# GD32A72_A74x register map
File version: 1.0
CPU: CM7 r2p1, little endian, MPU, FPU, DSP, 4 interrupt priority bits
Registers are 32-bit, read-write, reset 0x0 unless marked. A register's access mark holds for its fields unless they carry their own. Offsets are from the block's base; [hi:lo] are bit positions; {n}, {i} and the like mark numbered series.

## CMP1 — Comparator
Base 0x40016C00
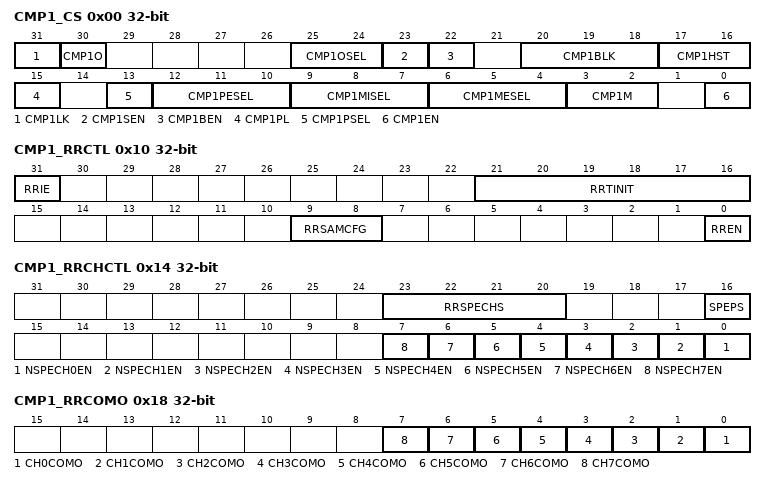
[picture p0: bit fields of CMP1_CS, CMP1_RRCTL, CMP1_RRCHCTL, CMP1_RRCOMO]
0x00 CMP1_CS access per field — CMP1 Control status register
  [31] CMP1LK rw — CMP1 lock
  [30] CMP1O ro — CMP1 output state
  [25:24] CMP1OSEL rw — CMP1 output selection
  [23] CMP1SEN rw — Voltage scaler enable bit
  [22] CMP1BEN rw — Scaler bridge enable bit
  [20:18] CMP1BLK rw — CMP1 output blanking source
  [17:16] CMP1HST rw — CMP1 hysteresis
  [15] CMP1PL rw — Polarity of CMP1 output
  [13] CMP1PSEL rw — CMP1_IP input selection
  [12:10] CMP1PESEL rw — CMP1_IP external input selection
  [9:7] CMP1MISEL rw — CMP1_IM internal input selection
  [6:4] CMP1MESEL rw — CMP1_IM external input selection
  [3:2] CMP1M rw — CMP1 mode
  [0] CMP1EN rw — CMP1 enable
0x10 CMP1_RRCTL — Round Robin control register
  [31] RRIE — Interrupt enable for Round-Robin
  [21:16] RRTINIT — Round-Robin time initialization
  [9:8] RRSAMCFG — Round-Robin sample clocks configuration
  [0] RREN — Round-Robin enable
0x14 CMP1_RRCHCTL — Round Robin channel control register
  [23:20] RRSPECHS — Round-Robin specified channel selection
  [16] SPEPS — Specified port selection
  [n] NSPECH{n}EN (n=0..7) — Non-specified mux port channel {n} enable
0x18 CMP1_RRCOMO — Round Robin compare output register
  [n] CH{n}COMO (n=0..7) — Channel {n} compare output state
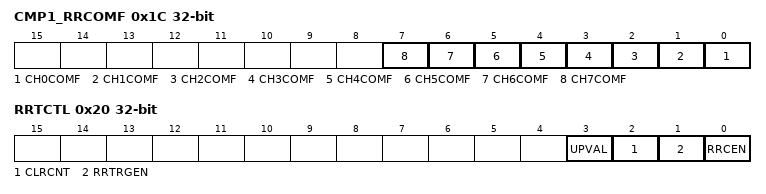
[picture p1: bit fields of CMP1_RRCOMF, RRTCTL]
0x1C CMP1_RRCOMF — Round Robin compare result flag register
  [n] CH{n}COMF (n=0..7) — Channel {n} compare result flag
0x20 RRTCTL — Round Robin timer control register
  [3] UPVAL — Write 1 to update the RRTVAL[31:0] value
  [2] CLRCNT — Write 1 to clear the RRCNT[31:0] value
  [1] RRTRGEN — Round Robin trigger enable
  [0] RRCEN — Round Robin counter enable
0x24 RRTTRGV — Round Robin timer trigger value register
  [31:0] RRTVAL — Round Robin timer trigger value
0x28 RRTCNT ro — Round Robin timer counter register
  [31:0] RRCNT — Round Robin timer count

## CPDM — Clock phase delay module
Base 0x49001800
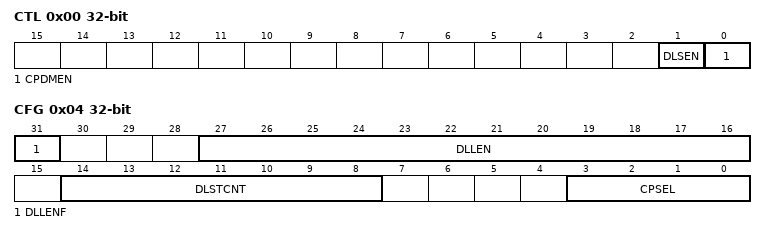
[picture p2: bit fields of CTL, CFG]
0x00 CTL — Control register
  [1] DLSEN — CPDM delay line sample module enable bit
  [0] CPDMEN — CPDM enable bit
0x04 CFG access per field — Configuration register
  [31] DLLENF ro — Valid mark of delay line length
  [27:16] DLLEN ro — Delay line length
  [14:8] DLSTCNT rw — Defines a delay step count for a unit delay UNIT
  [3:0] CPSEL rw — Output clock phase selection

## CRC — Cyclic redundancy checks management unit
Base 0x49003000
0x00 DATA reset 0xFFFFFFFF
  [31:0] DATA — CRC calculation result bits
0x04 FDATA — Free data register
  [7:0] FDATA — free data register bits
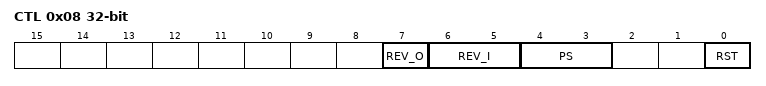
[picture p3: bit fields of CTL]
0x08 CTL — Control register
  [7] REV_O — reverse output data value in bit order
  [6:5] REV_I — reverse type for input data
  [4:3] PS — size of polynomial
  [0] RST — software writes and reads
0x10 IDATA reset 0xFFFFFFFF — Initialization Data Register
  [31:0] IDATA — configurable initial crc data value
0x14 POLY reset 0x4C11DB7 — Polynomial register
  [31:0] POLY — User configurable polynomial value

## DAC0 — Digital-to-analog converter
Base 0x40007400
Same registers: DAC1 0x4000CC00
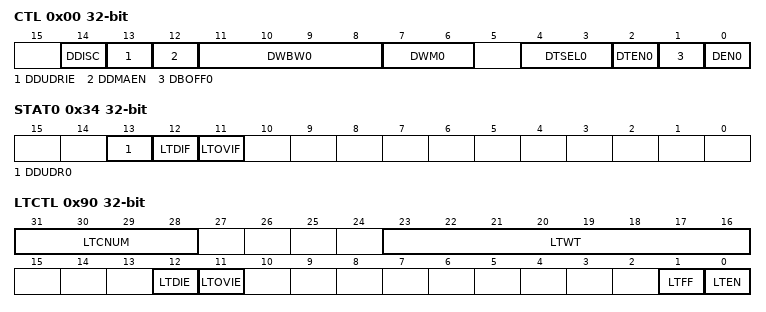
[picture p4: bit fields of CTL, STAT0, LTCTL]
0x00 CTL — Control register
  [14] DDISC — DAC_OUT0 connect GPIO selection
  [13] DDUDRIE — DAC_OUT0 DMA underrun interrupt enable
  [12] DDMAEN — DAC_OUT0 DMA enable
  [11:8] DWBW0 — DAC_OUT0 noise wave bit width
  [7:6] DWM0 — DAC_OUT0 noise wave mode
  [4:3] DTSEL0 — DAC_OUT0 trigger selection
  [2] DTEN0 — DAC_OUT0 trigger enable
  [1] DBOFF0 — DAC_OUT0 output buffer turn off
  [0] DEN0 — DAC_OUT0 enable
0x04 SWT wo — Software trigger register
  [0] SWTR0 — DAC_OUT0 software trigger, cleared by hardware
0x08 OUT0_R12DH — DACx_OUT0 12-bit right-aligned data holding register
  [11:0] OUT0_DH — DACx_OUT0 12-bit right-aligned data
0x0C OUT0_L12DH — DACx_OUT0 12-bit left-aligned data holding register
  [15:4] OUT0_DH — DACx_OUT0 12-bit left-aligned data
0x10 OUT0_R8DH — DACx_OUT0 8-bit right-aligned data holding register
  [7:0] OUT0_DH — DACx_OUT0 8-bit right-aligned data
0x2C OUT0_DO ro — DACx_OUT0 Data output register
  [11:0] OUT0_DO — DACx_OUT0 data output
0x34 STAT0 — Status register 0
  [13] DDUDR0 — DAC_OUT0 DMA underrun flag, set by hardware, cleared by software write 1
  [12] LTDIF — Loop test done interrupt flag, set by hardware, cleared by software write 1
  [11] LTOVIF — Loop test FIFO overflow interrupt flag, set by hardware, cleared by software write 1
0x90 LTCTL access per field — Loop test control register
  [31:28] LTCNUM ro — The remaining number of loop test pattern to be converted
  [23:16] LTWT rw — Loop test wait time
  [12] LTDIE rw — Loop test done interrupt enable
  [11] LTOVIE rw — Loop test overflow interrupt enable
  [1] LTFF rw — Loop test FIFO flush
  [0] LTEN rw — Loop test enable
0x94 LTPAT — Loop test pattern register
  [11:0] LTPAT — Loop test pattern
